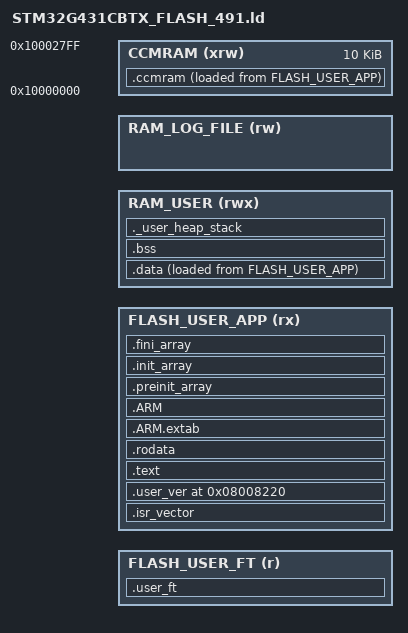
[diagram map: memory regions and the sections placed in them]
/**
 ******************************************************************************
 * @file      LinkerScript.ld
 * @author    Auto-generated by STM32CubeIDE
 * @brief     Linker script for STM32G431CBTx Device from STM32G4 series
 *                      128Kbytes FLASH
 *                      32Kbytes RAM
 *
 *            Set heap size, stack size and stack location according
 *            to application requirements.
 *
 *            Set memory bank area and size if external memory is used
 ******************************************************************************
 * @attention
 *
 * <h2><center>&copy; Copyright (c) 2020 STMicroelectronics.
 * All rights reserved.</center></h2>
 *
 * This software component is licensed by ST under BSD 3-Clause license,
 * the "License"; You may not use this file except in compliance with the
 * License. You may obtain a copy of the License at:
 *                        opensource.org/licenses/BSD-3-Clause
 *
 ******************************************************************************
 */

/* External linker file common to SAFE and USER project where partitioning 
* of the FLASH and RAM between SAFE and USER project is set.
* All further partitioning of the FLASH and RAM in this file is within boundaries
* set in memory_definition.ld file.*/
INCLUDE ../../submodules/versadrive_shared/memory_definition_491.ld

/* Entry Point */
ENTRY(User_Reset_Handler)

/* Highest address of the user mode stack */
/*_estack = ORIGIN(RAM) + LENGTH(RAM);    *//* end of "RAM" Ram type memory */

/* Highest address of the user mode stack */
/* Not used because USER application runs in SAFE context and therefore uses SAFE stack */
_estack = _MEMPART_RAM_USER_ADDR + _MEMPART_RAM_USER_SIZE - 1;    /* end of "RAM" Ram type memory */


/* Safe application Entry Point
** In case of USER application debugging this application will start with User_Reset_Handler
** and then jump to SAFE application first. Then USER application will be called from SAFE application.
*/ 
_safe_entry_start = _MEMPART_FLASH_SAFE_APP_ADDR + 4; /* Safe App .isr_vector address of Safe_Reset_Handler*/


/* USED for TEST logging */
RAM_LOG_FILE_SIZE = _MEMPART_RAM_LOG_FILE_SIZE;

_Min_Heap_Size  = 0x0400 ;    /* required amount of heap  */
_Min_Stack_Size = 0x0000 ;    /* required amount of stack */


/*
  FLASH  (rx )    : ORIGIN = 0x08000000,   LENGTH = 512K-2K
  CCMRAM (xrw)    : ORIGIN = 0x10000000,   LENGTH = 16K
  RAM    (xrw)    : ORIGIN = 0x20000000,   LENGTH = 96K-10K
*/  


/* Memories definition */
MEMORY
{
  FLASH_USER_FT   (r )    : ORIGIN = _MEMPART_FLASH_USER_FNC_TABLE_ADDR  ,LENGTH  = _MEMPART_FLASH_USER_FNC_TABLE_SIZE
  FLASH_USER_APP  (rx)    : ORIGIN = _MEMPART_FLASH_USER_APP_ADDR        ,LENGTH  = _MEMPART_FLASH_USER_APP_SIZE
        
  RAM_USER        (rwx)   : ORIGIN = _MEMPART_RAM_USER_ADDR              ,LENGTH  = _MEMPART_RAM_USER_SIZE
  RAM_LOG_FILE    (rw )   : ORIGIN = _MEMPART_RAM_LOG_FILE_ADDR          ,LENGTH  = _MEMPART_RAM_LOG_FILE_SIZE
  CCMRAM          (xrw)   : ORIGIN = 0x10000000,   LENGTH = 10K
  
    
}

/* Sections */
SECTIONS
{
  /* The startup code into "FLASH" Rom type memory */
  .isr_vector :
  {
    . = ALIGN(4);
    KEEP(*(.isr_vector)) /* Startup code */
    . = ALIGN(4);
  } >FLASH_USER_APP
  
  /* Location for Software version. */
  .user_ver 0x8008220:
  {
    *(.user_ver)
    *(.user_ver*)
    KEEP (*(.user_ver*))
    LONG(0x5245563C); /* ASCII chars "<VER" */

    *(.user_git_info)
    *(.user_git_info*)
    KEEP (*(.user_git_info*))
    LONG(0x5449473C); /* ASCII chars "<GIT" */
    
    *(.build_info)
    *(.build_info*)
    KEEP (*(.build_info*))    
  } >FLASH_USER_APP
  
 /*--- New CCMRAM linker section definition ---*/
 _siccmram = LOADADDR(.ccmram);
 /* CCMRAM section */
 .ccmram :
 {
     . = ALIGN(4);
     _sccmram = .; /* define a global symbols at ccmram start */
     *(.ccmram) 
     *(.ccmram*)
     . = ALIGN(4);
     _eccmram = .; /* define a global symbols at ccmram end */
 } >CCMRAM AT> FLASH_USER_APP
 /*--- End of CCMRAM linker section definition ---*/
  

  /* The program code and other data into "FLASH" Rom type memory */
  .text :
  {
    . = ALIGN(4);
    *(.text)           /* .text sections (code) */
    *(.text*)          /* .text* sections (code) */
    *(.glue_7)         /* glue arm to thumb code */
    *(.glue_7t)        /* glue thumb to arm code */
    *(.eh_frame)

    KEEP (*(.init))
    KEEP (*(.fini))

    . = ALIGN(4);
    _etext = .;        /* define a global symbols at end of code */
  } >FLASH_USER_APP

  /* Constant data into "FLASH" Rom type memory */
  .rodata :
  {
    . = ALIGN(4);
    *(.rodata)         /* .rodata sections (constants, strings, etc.) */
    *(.rodata*)        /* .rodata* sections (constants, strings, etc.) */
    . = ALIGN(4);
  } >FLASH_USER_APP

  .ARM.extab   : {
    . = ALIGN(4);
    *(.ARM.extab* .gnu.linkonce.armextab.*)
    . = ALIGN(4);
  } >FLASH_USER_APP

  .ARM : {
    . = ALIGN(4);
    __exidx_start = .;
    *(.ARM.exidx*)
    __exidx_end = .;
    . = ALIGN(4);
  } >FLASH_USER_APP

  .preinit_array     :
  {
    . = ALIGN(4);
    PROVIDE_HIDDEN (__preinit_array_start = .);
    KEEP (*(.preinit_array*))
    PROVIDE_HIDDEN (__preinit_array_end = .);
    . = ALIGN(4);
  } >FLASH_USER_APP

  .init_array :
  {
    . = ALIGN(4);
    PROVIDE_HIDDEN (__init_array_start = .);
    KEEP (*(SORT(.init_array.*)))
    KEEP (*(.init_array*))
    PROVIDE_HIDDEN (__init_array_end = .);
    . = ALIGN(4);
  } >FLASH_USER_APP

  .fini_array :
  {
    . = ALIGN(4);
    PROVIDE_HIDDEN (__fini_array_start = .);
    KEEP (*(SORT(.fini_array.*)))
    KEEP (*(.fini_array*))
    PROVIDE_HIDDEN (__fini_array_end = .);
    . = ALIGN(4);
  } >FLASH_USER_APP

  /* Used by the startup to initialize data */
  _sidata = LOADADDR(.data);

  /* Initialized data sections into "RAM" Ram type memory */
  .data :
  {
    . = ALIGN(4);
    _sdata = .;        /* create a global symbol at data start */
    *(.data)           /* .data sections */
    *(.data*)          /* .data* sections */
    *(.RamFunc)        /* .RamFunc sections */
    *(.RamFunc*)       /* .RamFunc* sections */

    . = ALIGN(4);
    _edata = .;        /* define a global symbol at data end */

  } >RAM_USER AT> FLASH_USER_APP


  /* Constant data into "FLASH_USER_APP" Rom type memory */
  .user_ft :
  {
    . = ALIGN(4);
    *(.user_ft)         /* .user_ft  safe functions pointer table */
    *(.user_ft*)        /* .user_ft* safe functions pointer table */

    KEEP (*(.user_ft*))
    
    . = ALIGN(4);
  } >FLASH_USER_FT
  
/*##########################################################################*/




  /* Uninitialized data section into "RAM" Ram type memory */
  . = ALIGN(4);
  .bss :
  {
    /* This is used by the startup in order to initialize the .bss section */
    _sbss = .;         /* define a global symbol at bss start */
    __bss_start__ = _sbss;
    *(.bss)
    *(.bss*)
    *(COMMON)

    . = ALIGN(4);
    _ebss = .;         /* define a global symbol at bss end */
    __bss_end__ = _ebss;
  } >RAM_USER

  /* User_heap_stack section, used to check that there is enough "RAM" Ram  type memory left */
  ._user_heap_stack :
  {
    . = ALIGN(8);
    PROVIDE ( end = . );
    PROVIDE ( _end = . );
    . = . + _Min_Heap_Size;
    . = . + _Min_Stack_Size;
    . = ALIGN(8);
  } >RAM_USER

  /* Remove information from the compiler libraries */
  /DISCARD/ :
  {
    libc.a ( * )
    libm.a ( * )
    libgcc.a ( * )
  }

  .ARM.attributes 0 : { *(.ARM.attributes) }
}
